AUTOSAR XML (schema 00043)
package /vector/diag_test_mediator
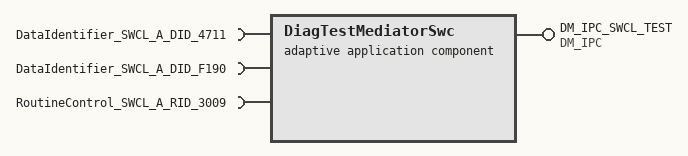
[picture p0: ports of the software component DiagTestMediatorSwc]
  adaptive application sw component type DiagTestMediatorSwc
    provide port DM_IPC_SWCL_TEST: provided-interface=DM_IPC
    require port DataIdentifier_SWCL_A_DID_4711: required-interface=DataIdentifier_SWCL_A_DID_4711
    require port DataIdentifier_SWCL_A_DID_F190: required-interface=DataIdentifier_SWCL_A_DID_F190
    require port RoutineControl_SWCL_A_RID_3009: required-interface=RoutineControl_SWCL_A_RID_3009
  executable DiagTestMediatorExe
    root sw component prototype DiagTestMediatorRootSwc: application-type=DiagTestMediatorSwc
  adaptive autosar application DiagTestMediator: category=APPLICATION_LEVEL, executable=DiagTestMediatorExe
